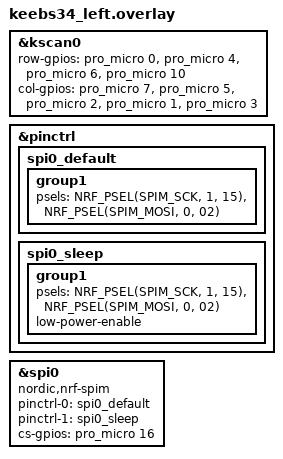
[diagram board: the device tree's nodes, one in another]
#include "keebs34.dtsi"

&kscan0 {
    row-gpios = <&pro_micro 0 (GPIO_ACTIVE_HIGH)>
                , <&pro_micro 4 (GPIO_ACTIVE_HIGH)>
                , <&pro_micro 6 (GPIO_ACTIVE_HIGH)>
                , <&pro_micro 10 (GPIO_ACTIVE_HIGH)>;

    col-gpios = <&pro_micro 7 (GPIO_ACTIVE_HIGH | GPIO_PULL_DOWN)>
                , <&pro_micro 5 (GPIO_ACTIVE_HIGH | GPIO_PULL_DOWN)>
                , <&pro_micro 2 (GPIO_ACTIVE_HIGH | GPIO_PULL_DOWN)>
                , <&pro_micro 1 (GPIO_ACTIVE_HIGH | GPIO_PULL_DOWN)>
                , <&pro_micro 3 (GPIO_ACTIVE_HIGH | GPIO_PULL_DOWN)>;
};

&pinctrl {
    spi0_default: spi0_default {
        group1 {
            psels = <NRF_PSEL(SPIM_SCK, 1, 15)>,
                    <NRF_PSEL(SPIM_MOSI, 0, 02)>;
        };
    };

    spi0_sleep: spi0_sleep {
        group1 {
            psels = <NRF_PSEL(SPIM_SCK, 1, 15)>,
                    <NRF_PSEL(SPIM_MOSI, 0, 02)>;
            low-power-enable;
        };
    };
};

nice_view_spi: &spi0 {
    compatible = "nordic,nrf-spim";
    pinctrl-0 = <&spi0_default>;
    pinctrl-1 = <&spi0_sleep>;
    pinctrl-names = "default", "sleep";
    cs-gpios = <&pro_micro 16 GPIO_ACTIVE_HIGH>; //nice!nano 011
    status = "okay";
};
